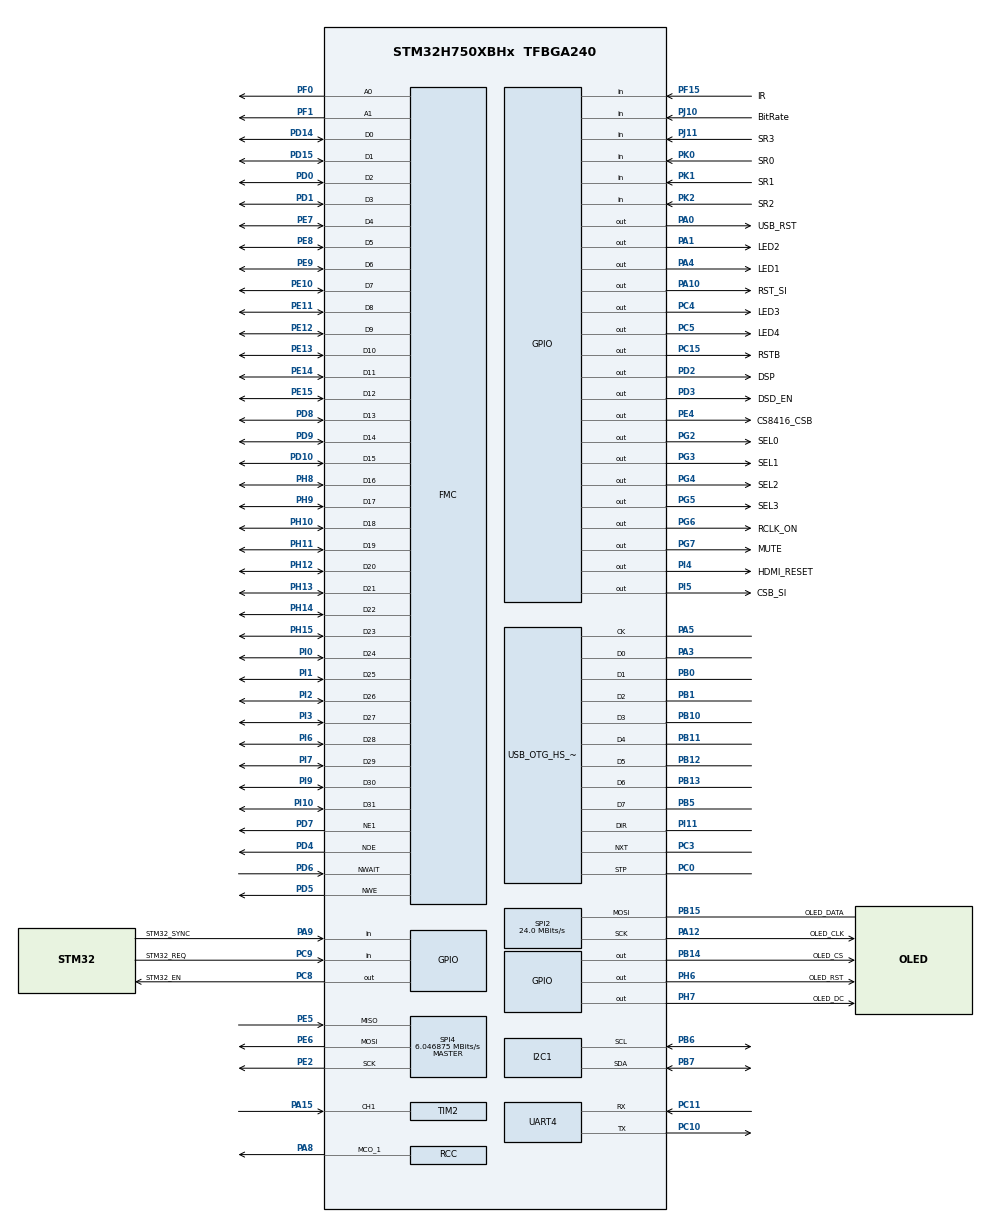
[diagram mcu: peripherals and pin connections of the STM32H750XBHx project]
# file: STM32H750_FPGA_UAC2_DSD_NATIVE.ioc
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CORTEX_M7.AccessPermission_S-Cortex_Memory_Protection_Unit_Region3_Settings_S=MPU_REGION_FULL_ACCESS
CORTEX_M7.AccessPermission_S-Cortex_Memory_Protection_Unit_Region5_Settings_S=MPU_REGION_FULL_ACCESS
CORTEX_M7.BaseAddress_S-Cortex_Memory_Protection_Unit_Region3_Settings_S=0x30000000
CORTEX_M7.BaseAddress_S-Cortex_Memory_Protection_Unit_Region5_Settings_S=0x60000000
CORTEX_M7.CPU_DCache=Enabled
CORTEX_M7.CPU_ICache=Enabled
CORTEX_M7.DisableExec_S-Cortex_Memory_Protection_Unit_Region3_Settings_S=MPU_INSTRUCTION_ACCESS_DISABLE
CORTEX_M7.DisableExec_S-Cortex_Memory_Protection_Unit_Region5_Settings_S=MPU_INSTRUCTION_ACCESS_DISABLE
CORTEX_M7.Enable_S-Cortex_Memory_Protection_Unit_Region3_Settings_S=MPU_REGION_ENABLE
CORTEX_M7.Enable_S-Cortex_Memory_Protection_Unit_Region5_Settings_S=MPU_REGION_ENABLE
CORTEX_M7.IsBufferable_S-Cortex_Memory_Protection_Unit_Region5_Settings_S=MPU_ACCESS_BUFFERABLE
CORTEX_M7.IsShareable_S-Cortex_Memory_Protection_Unit_Region3_Settings_S=MPU_ACCESS_SHAREABLE
CORTEX_M7.IsShareable_S-Cortex_Memory_Protection_Unit_Region5_Settings_S=MPU_ACCESS_SHAREABLE
CORTEX_M7.Size_S-Cortex_Memory_Protection_Unit_Region3_Settings_S=MPU_REGION_SIZE_1MB
CORTEX_M7.Size_S-Cortex_Memory_Protection_Unit_Region5_Settings_S=MPU_REGION_SIZE_2MB
CORTEX_M7.default_mode_Activation=1
FMC.AddressSetupTime1=3
FMC.BusTurnAroundDuration1=1
FMC.DataSetupTime1=20
FMC.ExtendedMode1=FMC_EXTENDED_MODE_DISABLE
FMC.WriteFifo1=FMC_WRITE_FIFO_DISABLE
FMC.WriteOperation1=FMC_WRITE_OPERATION_ENABLE
I2C1.Timing=0x307075B1
Mcu.Family=STM32H7
Mcu.Name=STM32H750XBHx
Mcu.Package=TFBGA240
NVIC.OTG_HS_IRQn=true\:0\:0\:false\:false\:true\:true\:true\:true
NVIC.PriorityGroup=NVIC_PRIORITYGROUP_4
NVIC.TIM3_IRQn=true\:4\:0\:true\:false\:true\:true\:true\:true
PA0.GPIO_Label=USB_RST
PA0.GPIO_PuPd=GPIO_NOPULL
PA0.GPIO_Speed=GPIO_SPEED_FREQ_MEDIUM
PA0.PinState=GPIO_PIN_SET
PA0.Signal=GPIO_Output
PA1.GPIO_Label=LED2
PA1.Signal=GPIO_Output
PA10.GPIO_Label=RST_SI
PA10.GPIO_Speed=GPIO_SPEED_FREQ_MEDIUM
PA10.PinState=GPIO_PIN_SET
PA10.Signal=GPIO_Output
PA12.GPIO_Label=OLED_CLK
PA12.Mode=Simplex_Bidirectional_Master
PA12.Signal=SPI2_SCK
PA15\ (JTDI).Signal=S_TIM2_CH1_ETR
PA3.Mode=Device_HS
PA3.Signal=USB_OTG_HS_ULPI_D0
PA4.GPIO_Label=LED1
PA4.Signal=GPIO_Output
PA5.Mode=Device_HS
PA5.Signal=USB_OTG_HS_ULPI_CK
PA8.Mode=Clock-out-1
PA8.Signal=RCC_MCO_1
PA9.GPIO_Label=STM32_SYNC
PA9.GPIO_PuPd=GPIO_PULLUP
PA9.Signal=GPIO_Input
PB0.Mode=Device_HS
PB0.Signal=USB_OTG_HS_ULPI_D1
PB1.Mode=Device_HS
PB1.Signal=USB_OTG_HS_ULPI_D2
PB10.Mode=Device_HS
PB10.PinAttribute=Free
PB10.Signal=USB_OTG_HS_ULPI_D3
PB11.Mode=Device_HS
PB11.PinAttribute=Free
PB11.Signal=USB_OTG_HS_ULPI_D4
PB12.Mode=Device_HS
PB12.Signal=USB_OTG_HS_ULPI_D5
PB13.Mode=Device_HS
PB13.Signal=USB_OTG_HS_ULPI_D6
PB14.GPIO_Label=OLED_CS
PB14.Signal=GPIO_Output
PB15.GPIO_Label=OLED_DATA
PB15.Mode=Simplex_Bidirectional_Master
PB15.Signal=SPI2_MOSI
PB5.Mode=Device_HS
PB5.Signal=USB_OTG_HS_ULPI_D7
PB6.Mode=I2C
PB6.Signal=I2C1_SCL
PB7.Mode=I2C
PB7.Signal=I2C1_SDA
PC0.Mode=Device_HS
PC0.PinAttribute=Free
PC0.Signal=USB_OTG_HS_ULPI_STP
PC10.Mode=Asynchronous
PC10.Signal=UART4_TX
PC11.Mode=Asynchronous
PC11.Signal=UART4_RX
PC15-OSC32_OUT\ (OSC32_OUT).GPIO_Label=RSTB
PC15-OSC32_OUT\ (OSC32_OUT).Signal=GPIO_Output
PC3.Mode=Device_HS
PC3.PinAttribute=Free
PC3.Signal=USB_OTG_HS_ULPI_NXT
PC4.GPIO_Label=LED3
PC4.Signal=GPIO_Output
PC5.GPIO_Label=LED4
PC5.Signal=GPIO_Output
PC8.GPIO_Label=STM32_EN
PC8.GPIO_PuPd=GPIO_PULLUP
PC8.Signal=GPIO_Output
PC9.GPIO_Label=STM32_REQ
PC9.GPIO_PuPd=GPIO_PULLUP
PC9.Signal=GPIO_Input
PD0.Signal=FMC_D2_DA2
PD1.Signal=FMC_D3_DA3
PD10.Signal=FMC_D15_DA15
PD14.Signal=FMC_D0_DA0
PD15.Signal=FMC_D1_DA1
PD2.GPIO_Label=DSP
PD2.Signal=GPIO_Output
PD3.GPIO_Label=DSD_EN
PD3.Signal=GPIO_Output
PD4.GPIO_PuPd=GPIO_PULLUP
PD4.Signal=FMC_NOE
PD5.GPIO_PuPd=GPIO_PULLUP
PD5.Signal=FMC_NWE
PD6.GPIO_PuPd=GPIO_PULLUP
PD6.Signal=FMC_NWAIT
PD7.Mode=NorPsramChipSelect1_1
PD7.Signal=FMC_NE1
PD8.Signal=FMC_D13_DA13
PD9.Signal=FMC_D14_DA14
PE10.PinAttribute=Free
PE10.Signal=FMC_D7_DA7
PE11.PinAttribute=Free
PE11.Signal=FMC_D8_DA8
PE12.Signal=FMC_D9_DA9
PE13.Signal=FMC_D10_DA10
PE14.Signal=FMC_D11_DA11
PE15.Signal=FMC_D12_DA12
PE2.Mode=Full_Duplex_Master
PE2.Signal=SPI4_SCK
PE4.GPIO_Label=CS8416_CSB
PE4.Signal=GPIO_Output
PE5.Mode=Full_Duplex_Master
PE5.Signal=SPI4_MISO
PE6.Mode=Full_Duplex_Master
PE6.Signal=SPI4_MOSI
PE7.Signal=FMC_D4_DA4
PE8.Signal=FMC_D5_DA5
PE9.PinAttribute=Free
PE9.Signal=FMC_D6_DA6
PF0.PinAttribute=Free
PF0.Signal=FMC_A0
PF1.PinAttribute=Free
PF1.Signal=FMC_A1
PF15.GPIO_Label=IR
PF15.Signal=GPIO_Input
PG2.GPIO_Label=SEL0
PG2.GPIO_PuPd=GPIO_PULLDOWN
PG2.Signal=GPIO_Output
PG3.GPIO_Label=SEL1
PG3.GPIO_PuPd=GPIO_PULLDOWN
PG3.Signal=GPIO_Output
PG4.GPIO_Label=SEL2
PG4.GPIO_PuPd=GPIO_PULLDOWN
PG4.Signal=GPIO_Output
PG5.GPIO_Label=SEL3
PG5.GPIO_PuPd=GPIO_PULLDOWN
PG5.Signal=GPIO_Output
PG6.GPIO_Label=RCLK_ON
PG6.Signal=GPIO_Output
PG7.GPIO_Label=MUTE
PG7.Signal=GPIO_Output
PH0-OSC_IN\ (PH0).Mode=HSE-External-Clock-Source
PH0-OSC_IN\ (PH0).PinAttribute=Free
PH0-OSC_IN\ (PH0).Signal=RCC_OSC_IN
PH10.Signal=FMC_D18
PH11.Signal=FMC_D19
PH12.Signal=FMC_D20
PH13.Signal=FMC_D21
PH14.Signal=FMC_D22
PH15.Signal=FMC_D23
PH6.GPIO_Label=OLED_RST
PH6.Signal=GPIO_Output
PH7.GPIO_Label=OLED_DC
PH7.Signal=GPIO_Output
PH8.Signal=FMC_D16
PH9.Signal=FMC_D17
PI0.Signal=FMC_D24
PI1.Signal=FMC_D25
PI10.PinAttribute=Free
PI10.Signal=FMC_D31
PI11.Mode=Device_HS
PI11.PinAttribute=Free
PI11.Signal=USB_OTG_HS_ULPI_DIR
PI2.Signal=FMC_D26
PI3.Signal=FMC_D27
PI4.GPIO_Label=HDMI_RESET
PI4.Signal=GPIO_Output
PI5.GPIO_Label=CSB_SI
PI5.Signal=GPIO_Output
PI6.Signal=FMC_D28
PI7.Signal=FMC_D29
PI9.Signal=FMC_D30
PJ10.GPIO_Label=BitRate
PJ10.Signal=GPIO_Input
PJ11.GPIO_Label=SR3
PJ11.Signal=GPIO_Input
PK0.GPIO_Label=SR0
PK0.Signal=GPIO_Input
PK1.GPIO_Label=SR1
PK1.Signal=GPIO_Input
PK2.GPIO_Label=SR2
PK2.Signal=GPIO_Input
ProjectManager.HeapSize=0x200
ProjectManager.StackSize=0x400
ProjectManager.TargetToolchain=STM32CubeIDE
RCC.ADCFreq_Value=96750000
RCC.APB1Freq_Value=120000000
RCC.APB2Freq_Value=120000000
RCC.APB3Freq_Value=120000000
RCC.APB4Freq_Value=120000000
RCC.CortexFreq_Value=480000000
RCC.D1PPRE=RCC_APB3_DIV2
RCC.D2PPRE1=RCC_APB1_DIV2
RCC.D2PPRE2=RCC_APB2_DIV2
RCC.D3PPRE=RCC_APB4_DIV2
RCC.DIVM1=12
RCC.DIVN1=240
RCC.DIVQ1=20
RCC.HCLKFreq_Value=240000000
RCC.HPRE=RCC_HCLK_DIV2
RCC.HSE_VALUE=48000000
RCC.PLLSourceVirtual=RCC_PLLSOURCE_HSE
RCC.RCC_MCO1Source=RCC_MCO1SOURCE_PLL1QCLK
RCC.RCC_MCODiv1=RCC_MCODIV_2
RCC.SYSCLKFreq_VALUE=480000000
RCC.SYSCLKSource=RCC_SYSCLKSOURCE_PLLCLK
RCC.Spi45ClockSelection=RCC_SPI45CLKSOURCE_PLL3
RCC.USBFreq_Value=48000000
SH.FMC_A0.0=FMC_A0,2b-a1
SH.FMC_A1.0=FMC_A1,2b-a1
SH.FMC_D0_DA0.0=FMC_D0,32b-d1
SH.FMC_D10_DA10.0=FMC_D10,32b-d1
SH.FMC_D11_DA11.0=FMC_D11,32b-d1
SH.FMC_D12_DA12.0=FMC_D12,32b-d1
SH.FMC_D13_DA13.0=FMC_D13,32b-d1
SH.FMC_D14_DA14.0=FMC_D14,32b-d1
SH.FMC_D15_DA15.0=FMC_D15,32b-d1
SH.FMC_D16.0=FMC_D16,32b-d1
SH.FMC_D17.0=FMC_D17,32b-d1
SH.FMC_D18.0=FMC_D18,32b-d1
SH.FMC_D19.0=FMC_D19,32b-d1
SH.FMC_D1_DA1.0=FMC_D1,32b-d1
SH.FMC_D20.0=FMC_D20,32b-d1
SH.FMC_D21.0=FMC_D21,32b-d1
SH.FMC_D22.0=FMC_D22,32b-d1
SH.FMC_D23.0=FMC_D23,32b-d1
SH.FMC_D24.0=FMC_D24,32b-d1
SH.FMC_D25.0=FMC_D25,32b-d1
SH.FMC_D26.0=FMC_D26,32b-d1
SH.FMC_D27.0=FMC_D27,32b-d1
SH.FMC_D28.0=FMC_D28,32b-d1
SH.FMC_D29.0=FMC_D29,32b-d1
SH.FMC_D2_DA2.0=FMC_D2,32b-d1
SH.FMC_D30.0=FMC_D30,32b-d1
SH.FMC_D31.0=FMC_D31,32b-d1
SH.FMC_D3_DA3.0=FMC_D3,32b-d1
SH.FMC_D4_DA4.0=FMC_D4,32b-d1
SH.FMC_D5_DA5.0=FMC_D5,32b-d1
SH.FMC_D6_DA6.0=FMC_D6,32b-d1
SH.FMC_D7_DA7.0=FMC_D7,32b-d1
SH.FMC_D8_DA8.0=FMC_D8,32b-d1
SH.FMC_D9_DA9.0=FMC_D9,32b-d1
SH.FMC_NOE.0=FMC_NOE,Sram1
SH.FMC_NWAIT.0=FMC_NWAIT,AsynchronousWait1
SH.FMC_NWE.0=FMC_NWE,Sram1
SH.S_TIM2_CH1_ETR.0=TIM2_CH1,TriggerSource_TI1FP1
SPI2.CalculateBaudRate=24.0 MBits/s
SPI2.Direction=SPI_DIRECTION_1LINE
SPI2.Mode=SPI_MODE_MASTER
SPI2.VirtualType=VM_MASTER
SPI4.BaudRatePrescaler=SPI_BAUDRATEPRESCALER_16
SPI4.CLKPhase=SPI_PHASE_1EDGE
SPI4.CalculateBaudRate=6.046875 MBits/s
SPI4.DataSize=SPI_DATASIZE_8BIT
SPI4.Direction=SPI_DIRECTION_2LINES
SPI4.Mode=SPI_MODE_MASTER
SPI4.VirtualType=VM_MASTER
TIM2.Slave_TriggerFilter=4
USB_OTG_HS.VirtualMode-Device_HS=Device_HS
VP_MEMORYMAP_VS_MEMORYMAP.Mode=CurAppReg
VP_TIM2_VS_ControllerModeClock.Mode=Clock Mode
VP_TIM3_VS_ClockSourceINT.Mode=Internal
board=custom

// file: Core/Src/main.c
/* USER CODE BEGIN Header */
/**
  ******************************************************************************
  * @file           : main.c
  * @brief          : Main program body
  ******************************************************************************
  * @attention
  *
  * Copyright (c) 2026 STMicroelectronics.
  * All rights reserved.
  *
  * This software is licensed under terms that can be found in the LICENSE file
  * in the root directory of this software component.
  * If no LICENSE file comes with this software, it is provided AS-IS.
  *
  ******************************************************************************
  */
/* USER CODE END Header */
#include "main.h"
#include "i2c.h"
#include "memorymap.h"
#include "spi.h"
#include "tim.h"
#include "usart.h"
#include "usb_otg.h"
#include "gpio.h"
#include "fmc.h"

/* USER CODE BEGIN Includes */
#include "usb_device.h"
#include "usbd_conf.h"
#include "IRremote.h"
#include "adv7611.h"
#include "CS8416.h"
#include "SI5340.h"
#include <stdbool.h>
#include "dac_gui.h"
#include <math.h>
#include <stdint.h>
#include "audio_buffer.h"
#include "bus_poll_fpga.h"
#include <stdio.h>

/* USER CODE END Includes */

/* USER CODE BEGIN PTD */
void IR_TIM3_PeriodElapsedCallback(void); // RC5/IRremote.c’den
int SampleRate_Init_Si5340(uint32_t fs);
static   uint8_t first=1;
extern ui_state_t ui_cur;
extern uint8_t fpga_data_changed;
extern uint8_t rc5_changed;
uint32_t t_poll = 0;
static uint32_t t_dbg  = 0;
extern volatile uint32_t g_fs_pending;
extern volatile uint8_t  g_fs_apply_req;
extern volatile uint8_t  g_audio_run;
extern uint32_t g_fs_i2s;
static   uint8_t stm32_chg=0;
extern volatile uint32_t g_fpga_req_low_streak_max;
extern UART_HandleTypeDef huart4;
extern volatile int32_t  g_usb_fb_adj;   /* Adaptive feedback offset (usbd_audio.c) */
extern int SI5340_DCO_Init_N1(void);
extern int SI5340_DCO_FINC_N1(uint16_t steps);
extern int SI5340_DCO_FDEC_N1(uint16_t steps);
extern int SI5340_DCO_Recenter_N1(void);
extern int32_t SI5340_DCO_GetN1OffsetSteps(void);
static volatile uint8_t  g_fifo_resync_req = 0u; /* FIFO graceful resync isteği */
static volatile uint8_t  g_si5340_dco_ready = 0u;
/* USER CODE END PTD */

void SystemClock_Config(void);
void PeriphCommonClock_Config(void);
static void MPU_Config(void);

/* USER CODE BEGIN 0 */
void HAL_TIM_PeriodElapsedCallback(TIM_HandleTypeDef *htim)
{
    if (htim->Instance == TIM3)
    {
        IR_TIM3_PeriodElapsedCallback();
        return;
    }
}

static inline void dwt_init(void)
{
    CoreDebug->DEMCR |= CoreDebug_DEMCR_TRCENA_Msk;
    DWT->CYCCNT = 0;
    DWT->CTRL |= DWT_CTRL_CYCCNTENA_Msk;
}

static uint8_t  prev_src = 0xFF;
static uint8_t  prev_audio_on = 0x00;

static inline bool time_due(uint32_t now, uint32_t *t_next, uint32_t period_ms)
{
    if ((int32_t)(now - *t_next) >= 0) {
        *t_next += period_ms;     // drift-free pacing
        return true;
    }
    return false;
}

static inline uint8_t si5340_profile_has_dco(uint32_t fs_or_clk)
{
    /* DCO (Digital Controlled Oscillator) destekleyen profiller.
     * Kriter: Si5340_REG_N_FSTEP_MSK != 0 (ilgili .h dosyasinda 0x0339 kaydi)
     *   44.h  → 0x1D (N1 only)   88.h  → 0x1D   176.h → 0x1D
     *   352.h → 0x1F (all N)   (352800 Hz / DSD512 profili de DCO destekler)
     * PCM base rate veya dogrudan DSD clock Hz cinsinden kabul edilir.
     */
    return (fs_or_clk == 44100u   || fs_or_clk == 2822400u  ||
            fs_or_clk == 88200u   || fs_or_clk == 5644800u  ||
            fs_or_clk == 176400u  || fs_or_clk == 11289600u ||
            fs_or_clk == 352800u  || fs_or_clk == 22579200u ||
            fs_or_clk == 705600u  || fs_or_clk == 44158400u) ? 1u : 0u;
}
/* USER CODE END 0 */

int main(void)
{

  /* MPU Configuration--------------------------------------------------------*/
  MPU_Config();

  /* Enable the CPU Cache */

  /* Enable I-Cache---------------------------------------------------------*/
  SCB_EnableICache();

  /* Enable D-Cache---------------------------------------------------------*/
  SCB_EnableDCache();

  /* MCU Configuration--------------------------------------------------------*/

  /* Reset of all peripherals, Initializes the Flash interface and the Systick. */
  HAL_Init();

  /* USER CODE BEGIN Init */
  SCB->CCR &= ~(1u<<3);
   MX_GPIO_Init();
   LL_GPIO_ResetOutputPin(GPIOA, USB_RST_Pin);
   HAL_Delay(100);
  /* USER CODE END Init */

  /* Configure the system clock */
  SystemClock_Config();

  /* Configure the peripherals common clocks */
  PeriphCommonClock_Config();

  /* USER CODE BEGIN SysInit */
  LL_GPIO_SetOutputPin(GPIOI, RST_SI_Pin);

   LL_GPIO_ResetOutputPin(GPIOA, USB_RST_Pin);
   LL_GPIO_ResetOutputPin(GPIOI, HDMI_RESET_Pin);

   HAL_Delay(30);
   LL_GPIO_SetOutputPin(GPIOA, USB_RST_Pin);
   LL_GPIO_SetOutputPin(GPIOI, HDMI_RESET_Pin);

   HAL_Delay(30);
  /* USER CODE END SysInit */

  /* Initialize all configured peripherals */
  MX_GPIO_Init();
  MX_FMC_Init();
  MX_I2C1_Init();
  MX_SPI2_Init();
  MX_SPI4_Init();
  MX_TIM3_Init();
  MX_USB_OTG_HS_PCD_Init();
  MX_UART4_Init();
  MX_TIM2_Init();
  /* USER CODE BEGIN 2 */
  my_enableIRIn();
     MX_USB_DEVICE_Init();

            // LL_GPIO_ResetOutputPin(GPIOC, DSP_Pin);
            // LL_GPIO_ResetOutputPin(GPIOC, RCLK_ON_Pin);
             LL_GPIO_ResetOutputPin(GPIOC, RSTB_Pin);
             HAL_Delay(1);
             App_Init_Si5340();

             if ( ADV7611_Init()==0){
                	  while(1);
                  }

             EDID_Conf();
             CS8416_Init();

             dwt_init();
             //CS8416_SetOutputFormat_I2S();

            // bus_dma_tim1_init(240000000u);
             SampleRate_Init_Si5340(44100);
           //  bus_dma_tim1_set_fs(44100u);

             LL_GPIO_ResetOutputPin(MUTE_GPIO_Port, MUTE_Pin);
            // bus_dma_tim1_start();
             //static uint32_t t0 = 0;

             AudioBuffer_Init(AudioBuffer_Instance(), 0);  /* ring buffer sıfırla */
                bus_poll_init();
                fpga_set_stream_en(0);                        /* başlangıçta stream kapalı */
                SampleRate_Init_Si5340(44100u);
                g_si5340_dco_ready = si5340_profile_has_dco(44100u);
                if (g_si5340_dco_ready) {
                    SI5340_DCO_Init_N1();
                    SI5340_DCO_Recenter_N1();
                }
            // static uint32_t g_fs_pending_old = 44100;
  /* USER CODE END 2 */

  /* Infinite loop */
  /* USER CODE BEGIN WHILE */
                while (1)
                                {

                          	  // debug_audio_print_once(&huart4, 2000);

                          	     uint32_t now = HAL_GetTick();

                                    /* ----------------------------------------------------
                                     * 1. Stream aktif mi?
                                     *    g_audio_run: USB ISO OUT başladığında UAC2 stack set eder.
                                     *    ui_cur.src == SRC_STM32: kullanıcı USB kaynağını seçmiş.
                                     * ---------------------------------------------------- */
                                    uint8_t audio_on = (g_audio_run && (ui_cur.src == SRC_STM32)) ? 1u : 0u;

                                    /* ----------------------------------------------------
                                     * 2. Stream durum geçişi
                                     * ---------------------------------------------------- */
                                    if (audio_on != prev_audio_on || ui_cur.src != prev_src)
                                    {
                                        prev_audio_on = audio_on;
                                        prev_src      = ui_cur.src;

                                        if (audio_on)
                                        {
                                            /* Stream başladı:
                                             *   a) MUTE: pre-fill tamamlanana kadar ses kesilir
                                             *   b) RESYNC: FPGA'daki kısmi L/R çiftini sil
                                             *   c) EN_STREAM yükselt: FPGA FIFO'yu flush eder (~640ns)
                                             *   d) FIFO ön doldurma: FPGA FIFO prog_empty (4096)
                                             *      eşiğini aşacak kadar veri birikmesini bekle.
                                             *      Beklenmezse FIFO bos baslar, her USB timing
                                             *      sapmasi FIFO'yu bosaltir → citirtilar.
                                             */
                                            LL_GPIO_SetOutputPin(MUTE_GPIO_Port, MUTE_Pin);
                                            HAL_Delay(3); /* Mute devresinin kapanmasini bekle */
                                            fpga_send_resync();
                                            fpga_set_stream_en(1);   /* AudioBuffer sifirla, s_running=1 */
                                            if (g_si5340_dco_ready) {
                                                SI5340_DCO_Recenter_N1();
                                            }

                                            /* AudioBuffer'in ~131072 byte birikmesini bekle */
                                            {
                                                uint32_t t0 = HAL_GetTick();
                                                while (AudioBuffer_LevelBytes(AudioBuffer_Instance()) < 131072u) {
                                                    if ((uint32_t)(HAL_GetTick() - t0) > 300u) break;
                                                }
                                            }
                                            /* FIFO'ya hizla ~8192 entry yaz (prog_empty esigini bol as) */
                                            bus_poll_service(8192u);
                                            HAL_Delay(5); /* FIFO cikisinin stabilize olmasini bekle */
                                            LL_GPIO_ResetOutputPin(MUTE_GPIO_Port, MUTE_Pin);
                                        }
                                        else
                                        {
                                            /* Stream durdu: once MUTE, sonra FPGA durdur
                                             * (ters sirada FPGA dururken ses yolu acik → pop) */
                                            LL_GPIO_SetOutputPin(MUTE_GPIO_Port, MUTE_Pin);
                                            HAL_Delay(3);
                                            fpga_set_stream_en(0);
                                        }

                                        apply_input_select(ui_cur.src);
                                    }

                                    /* ----------------------------------------------------
                                     * 3. Polling transfer — sadece stream aktifken
                                     *
                                     *    max_frames = 128:
                                     *      44.1kHz → 44 frame/ms → 128 frame ≈ 2.9ms
                                     *      384kHz  → 384 frame/ms → 128 frame ≈ 0.33ms
                                     *    Ana döngü her turda çağrılır; underrun olursa
                                     *    istatistikte görünür, ses kesilmez (FIFO zero-hold).
                                     * ---------------------------------------------------- */
                                    if (audio_on)
                                    {
                                        bus_poll_service(512u);
                                    }

                                    /* ----------------------------------------------------
                                     * 3b. Graceful FIFO Resync
                                     *
                                     * FPGA FIFO saat kaymasindan dolayi prog_empty'e
                                     * duserse ve USB adaptive feedback cevap vermezse,
                                     * crackling yerine ~25ms sessizlik ile FIFO yeniden
                                     * doldurulur. Akis: MUTE → FIFO flush → AudioBuffer
                                     * doldur → FIFO on-doldur → UNMUTE.
                                     *
                                     * DSD256: 131072 byte / 5.644MB/s = ~23ms doldurma
                                     * DSD64:  131072 byte / 1.411MB/s = ~93ms doldurma
                                     * ---------------------------------------------------- */
                                    if (audio_on && g_fifo_resync_req)
                                    {
                                        g_fifo_resync_req = 0u;
                                        g_usb_fb_adj      = 0;   /* adj sifirla: temiz baslangic */

                                        LL_GPIO_SetOutputPin(MUTE_GPIO_Port, MUTE_Pin); /* sus */
                                        HAL_Delay(3); /* Mute devresinin kapanmasini bekle */
                                        fpga_send_resync();
                                        if (g_si5340_dco_ready) {
                                            SI5340_DCO_Recenter_N1();
                                        }
                                        //fpga_set_stream_en(1);   /* AudioBuffer & FIFO sifirla */

                                        {
                                            uint32_t t0 = HAL_GetTick();
                                            while (AudioBuffer_LevelBytes(AudioBuffer_Instance()) < 131072u) {
                                                if ((uint32_t)(HAL_GetTick() - t0) > 400u) break;
                                            }
                                        }
                                        bus_poll_service(32768u); /* FIFO on-doldur */
                                        HAL_Delay(5); /* FIFO cikisinin stabilize olmasini bekle */
                                        LL_GPIO_ResetOutputPin(MUTE_GPIO_Port, MUTE_Pin); /* ses ac */
                                    }

                                    /* ----------------------------------------------------
                                     * 4. Sample rate değişimi
                                     *
                                     * PCM→DSD256 geçişinde iki ardışık rate değişimi olur:
                                     *   a) EP0_RxReady: g_fs_pending = DoP taşıyıcı (ör. 705600)
                                     *   b) enter_dop_mode_runtime() (USB ISR, 131072 byte bekleme
                                     *      sırasında): g_fs_pending = Si5340 frekansı (ör. 176400)
                                     *      ve aynı anda FPGA DSD moduna alınır.
                                     *
                                     * BUG (düzeltildi): Eski kodda (a) sonrası UNMUTE yapılıyor,
                                     * FPGA DSD modundayken Si5340 hâlâ yanlış frekansta → kare dalga.
                                     *
                                     * FIX: do...while(g_fs_apply_req) döngüsü — DoP tespiti
                                     * yeni bir g_fs_apply_req tetiklerse MUTE korunarak (b) de
                                     * uygulanır; UNMUTE yalnızca rate kararlı olduktan sonra yapılır.
                                     * ---------------------------------------------------- */
                                    if (audio_on && (g_fs_apply_req || stm32_chg))
                                    {
                                        LL_GPIO_SetOutputPin(MUTE_GPIO_Port, MUTE_Pin);   /* ses kes */
                                        HAL_Delay(10);

                                        do {
                                            /* --------------------------------------------------
                                             * ÖNCE temizle: SampleRate_Init_Si5340() içindeki
                                             * HAL_Delay(300) sırasında USB ISR enter_dop_mode_runtime()
                                             * çağırıp g_fs_apply_req=1 set edebilir.
                                             * Temizleme SONRAYA bırakılırsa ISR'nin set ettiği değer
                                             * hemen ezilir → do...while erken çıkar → UNMUTE yanlış
                                             * Si5340 frekansıyla yapılır → kare dalga.
                                             * Başa alınınca: ISR yeni rate'i set ederse döngü bir tur
                                             * daha döner ve g_fs_pending ile Si5340 yeniden yüklenir.
                                             * -------------------------------------------------- */
                                            g_fs_apply_req = 0u;
                                            stm32_chg      = 0u;
                                            g_usb_fb_adj   = 0;   /* Yeni sample rate, offset sifirla */

                                            AudioBuffer_Init(AudioBuffer_Instance(), 0);      /* ring sıfırla */
                                            SampleRate_Init_Si5340(g_fs_pending);             /* SI5340 (~315ms: 300ms HAL_Delay + lock) */
                                            g_si5340_dco_ready = si5340_profile_has_dco(g_fs_pending);
                                            if (g_si5340_dco_ready) {
                                                SI5340_DCO_Init_N1();
                                                SI5340_DCO_Recenter_N1();
                                            }
                                            fpga_send_resync();                               /* kısmi L/R temizle */
                                            fpga_set_stream_en(1);                            /* stream aç, s_running=1 */

                                            /* --------------------------------------------------
                                             * FIFO Ön Doldurma:
                                             * Bu bekleme sırasında USB ISR çalışır; DoP tespit
                                             * edilirse enter_dop_mode_runtime() g_fs_apply_req'u
                                             * tekrar set eder → döngü bir tur daha döner.
                                             * -------------------------------------------------- */
                                            {
                                                uint32_t t0 = HAL_GetTick();
                                                while (AudioBuffer_LevelBytes(AudioBuffer_Instance()) < 131072u) {
                                                    if ((uint32_t)(HAL_GetTick() - t0) > 300u) break;
                                                }
                                            }

                                        } while (g_fs_apply_req); /* DoP ikinci rate geçişi: MUTE korunarak uygula */

                                        /* FIFO'ya hizla ~8192 entry yaz (prog_empty eşiğini (~4096) bol aş) */
                                        bus_poll_service(32768u);

                                        HAL_Delay(15);
                                        LL_GPIO_ResetOutputPin(MUTE_GPIO_Port, MUTE_Pin); /* sesi aç */
                                    }

                                    /* ----------------------------------------------------
                                     * 5. Debug: stats + FPGA durum (2000ms)
                                     * ---------------------------------------------------- */
                                    if (g_dsd_mode != DSD_MODE_OFF && si5340_profile_has_dco(g_dsd_clock_hz)) {
                                    if (time_due(now, &t_dbg, 2000u) && audio_on)
                                    {
                                        /* Static buffer: HAL_UART_Transmit_IT async calisir,
                                         * stack frame cokmeleri onlemek icin static kullan. */
                                        static char dbg_buf[128];
                                        fpga_stats_t dbg = fpga_get_stats();
                                        uint32_t fpga_st = fpga_read_status();
                                        uint32_t ab_lvl  = AudioBuffer_LevelBytes(AudioBuffer_Instance());
                                        int32_t dco_off = SI5340_DCO_GetN1OffsetSteps();
                                        int  len = snprintf(dbg_buf, sizeof(dbg_buf),
                                            "under=%lu ovfl=%lu fr=%lu ab=%lu fpga=0x%02lX dco=%ld rs=%lu\r\n",
                                            (unsigned long)dbg.underruns,
                                            (unsigned long)dbg.overflows,
                                            (unsigned long)dbg.frames_sent,
                                            (unsigned long)ab_lvl,
                                            (unsigned long)(fpga_st & 0xFFu),
                                            (long)dco_off,
                                            (unsigned long)dbg.resync_count);
                                        HAL_UART_Transmit(&huart4, (uint8_t*)dbg_buf, (uint16_t)len, 10u);
                                        fpga_reset_stats();
                                    }

                                    /* ----------------------------------------------------
                                     * 6. FPGA durum sorgusu + adaptive feedback (200ms)
                                     * ---------------------------------------------------- */

                                    if (time_due(now, &t_poll, 20u))
                                    {
                                        poll_fpga_data();

                                        if (audio_on)
                                        {
                                            #define AB_TARGET        131072u
                                            #define AB_HIGH1         163840u
                                            #define AB_LOW1           98304u
                                            #define AB_LOW2           65536u
                                            #define AB_LOW3           32768u
                                            #define DCO_MAX_STEPS        780
                                            #define RESYNC_CNT            80   /* 80 x 20ms = 1.6 s */

                                            static uint16_t s_low_cnt = 0;
                                            uint32_t ab_lvl = AudioBuffer_LevelBytes(AudioBuffer_Instance());
                                            int32_t  dco_off = SI5340_DCO_GetN1OffsetSteps();

                                            g_usb_fb_adj = 0;   /* MPD feedback artik devre disi */

                                            if (ab_lvl < AB_LOW3)
                                            {
                                                /* cok kritik: hizli yavaslat */
                                                if (dco_off > -DCO_MAX_STEPS) SI5340_DCO_FDEC_N1(10);
                                                s_low_cnt++;
                                            }
                                            else if (ab_lvl < AB_LOW2)
                                            {
                                                if (dco_off > -DCO_MAX_STEPS) SI5340_DCO_FDEC_N1(5);
                                                s_low_cnt++;
                                            }
                                            else if (ab_lvl < AB_LOW1)
                                            {
                                                if (dco_off > -DCO_MAX_STEPS) SI5340_DCO_FDEC_N1(2);
                                                s_low_cnt = 0;
                                            }
                                            else if (ab_lvl > AB_HIGH1)
                                            {
                                                /* fazla doluyorsa biraz hizlandir */
                                                if (dco_off < DCO_MAX_STEPS) SI5340_DCO_FINC_N1(2);
                                                s_low_cnt = 0;
                                            }
                                            else
                                            {
                                                /* orta bolgede yavasca merkeze don */
                                                if (dco_off > 0) {
                                                    SI5340_DCO_FDEC_N1(1);
                                                } else if (dco_off < 0) {
                                                    SI5340_DCO_FINC_N1(1);
                                                }
                                                s_low_cnt = 0;
                                            }

                                            /* sadece uzun sure cok dusukse resync */
                                            if (s_low_cnt >= RESYNC_CNT) {
                                                g_fifo_resync_req = 0u;
                                                s_low_cnt = 0u;
                                            }
                                        }
                                        else
                                        {
                                            g_usb_fb_adj = 0;
                                        }
                                    }
                                   }
                                    /* ----------------------------------------------------
                                     * 7. FPGA I2S kaynak değişimi (ADV7611/CS8416)
                                     * ---------------------------------------------------- */
                                    if (fpga_data_changed || first)
                                    {
                                        first             = 0;
                                        fpga_data_changed = 0;

                                        if (ui_cur.src == SRC_I2S_FPGA) {
                                            SampleRate_Init_Si5340(g_fs_i2s);
                                            stm32_chg = 1u;
                                        }
                                    }

                                    /* ----------------------------------------------------
                                     * 8. IR remote
                                     * ---------------------------------------------------- */
                                    handle_rc5();
                                    rc5_changed = 0;

                                } /* while(1) */

    /* USER CODE END WHILE */

}

void SystemClock_Config(void)
{
  LL_FLASH_SetLatency(LL_FLASH_LATENCY_4);
  while(LL_FLASH_GetLatency()!= LL_FLASH_LATENCY_4)
  {
  }
  LL_PWR_ConfigSupply(LL_PWR_LDO_SUPPLY);
  LL_PWR_SetRegulVoltageScaling(LL_PWR_REGU_VOLTAGE_SCALE0);
  while (LL_PWR_IsActiveFlag_VOS() == 0)
  {
  }
  LL_RCC_HSE_EnableBypass();
  LL_RCC_HSE_Enable();

   /* Wait till HSE is ready */
  while(LL_RCC_HSE_IsReady() != 1)
  {

  }
  LL_RCC_PLL_SetSource(LL_RCC_PLLSOURCE_HSE);
  LL_RCC_PLL1P_Enable();
  LL_RCC_PLL1Q_Enable();
  LL_RCC_PLL1_SetVCOInputRange(LL_RCC_PLLINPUTRANGE_4_8);
  LL_RCC_PLL1_SetVCOOutputRange(LL_RCC_PLLVCORANGE_WIDE);
  LL_RCC_PLL1_SetM(12);
  LL_RCC_PLL1_SetN(240);
  LL_RCC_PLL1_SetP(2);
  LL_RCC_PLL1_SetQ(20);
  LL_RCC_PLL1_SetR(2);
  LL_RCC_PLL1_Enable();

   /* Wait till PLL is ready */
  while(LL_RCC_PLL1_IsReady() != 1)
  {
  }

   /* Intermediate AHB prescaler 2 when target frequency clock is higher than 80 MHz */
   LL_RCC_SetAHBPrescaler(LL_RCC_AHB_DIV_2);

  LL_RCC_SetSysClkSource(LL_RCC_SYS_CLKSOURCE_PLL1);

   /* Wait till System clock is ready */
  while(LL_RCC_GetSysClkSource() != LL_RCC_SYS_CLKSOURCE_STATUS_PLL1)
  {

  }
  LL_RCC_SetSysPrescaler(LL_RCC_SYSCLK_DIV_1);
  LL_RCC_SetAHBPrescaler(LL_RCC_AHB_DIV_2);
  LL_RCC_SetAPB1Prescaler(LL_RCC_APB1_DIV_2);
  LL_RCC_SetAPB2Prescaler(LL_RCC_APB2_DIV_2);
  LL_RCC_SetAPB3Prescaler(LL_RCC_APB3_DIV_2);
  LL_RCC_SetAPB4Prescaler(LL_RCC_APB4_DIV_2);
  LL_SetSystemCoreClock(480000000);

   /* Update the time base */
  if (HAL_InitTick (TICK_INT_PRIORITY) != HAL_OK)
  {
    Error_Handler();
  }
  LL_RCC_ConfigMCO(LL_RCC_MCO1SOURCE_PLL1QCLK, LL_RCC_MCO1_DIV_2);
}

void PeriphCommonClock_Config(void)
{
  LL_RCC_PLL3Q_Enable();
  LL_RCC_PLL3_SetVCOInputRange(LL_RCC_PLLINPUTRANGE_1_2);
  LL_RCC_PLL3_SetVCOOutputRange(LL_RCC_PLLVCORANGE_WIDE);
  LL_RCC_PLL3_SetM(32);
  LL_RCC_PLL3_SetN(129);
  LL_RCC_PLL3_SetP(2);
  LL_RCC_PLL3_SetQ(2);
  LL_RCC_PLL3_SetR(2);
  LL_RCC_PLL3_Enable();

   /* Wait till PLL is ready */
  while(LL_RCC_PLL3_IsReady() != 1)
  {
  }

}

 /* MPU Configuration */

void MPU_Config(void)
{
  MPU_Region_InitTypeDef MPU_InitStruct = {0};

  /* Disables the MPU */
  HAL_MPU_Disable();

  /** Initializes and configures the Region and the memory to be protected
  */
  MPU_InitStruct.Enable = MPU_REGION_ENABLE;
  MPU_InitStruct.Number = MPU_REGION_NUMBER0;
  MPU_InitStruct.BaseAddress = 0x0;
  MPU_InitStruct.Size = MPU_REGION_SIZE_4GB;
  MPU_InitStruct.SubRegionDisable = 0x87;
  MPU_InitStruct.TypeExtField = MPU_TEX_LEVEL0;
  MPU_InitStruct.AccessPermission = MPU_REGION_NO_ACCESS;
  MPU_InitStruct.DisableExec = MPU_INSTRUCTION_ACCESS_DISABLE;
  MPU_InitStruct.IsShareable = MPU_ACCESS_SHAREABLE;
  MPU_InitStruct.IsCacheable = MPU_ACCESS_NOT_CACHEABLE;
  MPU_InitStruct.IsBufferable = MPU_ACCESS_NOT_BUFFERABLE;

  HAL_MPU_ConfigRegion(&MPU_InitStruct);

  /** Initializes and configures the Region and the memory to be protected
  */
  MPU_InitStruct.Number = MPU_REGION_NUMBER3;
  MPU_InitStruct.BaseAddress = 0x30000000;
  MPU_InitStruct.Size = MPU_REGION_SIZE_1MB;
  MPU_InitStruct.SubRegionDisable = 0x0;
  MPU_InitStruct.AccessPermission = MPU_REGION_FULL_ACCESS;

  HAL_MPU_ConfigRegion(&MPU_InitStruct);

  /** Initializes and configures the Region and the memory to be protected
  */
  MPU_InitStruct.Number = MPU_REGION_NUMBER5;
  MPU_InitStruct.BaseAddress = 0x60000000;
  MPU_InitStruct.Size = MPU_REGION_SIZE_2MB;
  MPU_InitStruct.IsBufferable = MPU_ACCESS_BUFFERABLE;

  HAL_MPU_ConfigRegion(&MPU_InitStruct);
  /* Enables the MPU */
  HAL_MPU_Enable(MPU_PRIVILEGED_DEFAULT);

}

void Error_Handler(void)
{
  __disable_irq();
  while (1)
  {
  }
}
